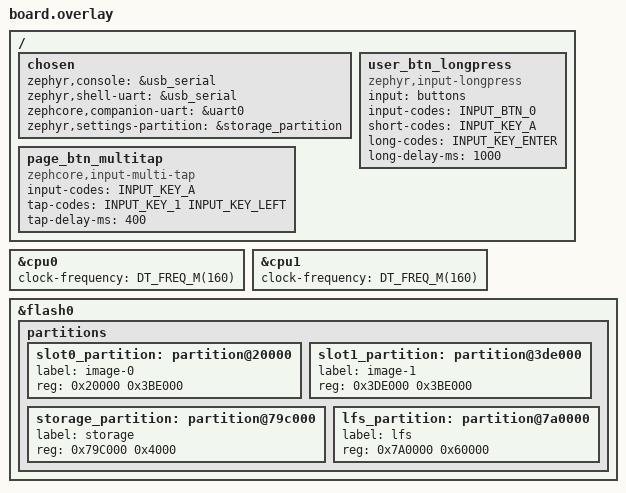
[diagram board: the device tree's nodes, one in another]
/*
 * SPDX-License-Identifier: MIT
 * LilyGo T3S3 v1.x — ZephCore-specific integration
 *
 * This overlay adds ZephCore-specific integration on top of the hardware DTS.
 * All fixed hardware (LoRa, OLED, button, ADC) is in lilygo_t3s3_procpu.dts.
 *
 * Only ZephCore-specific concerns go here:
 * - Input longpress/multitap chains
 * - Flash partition repartitioning for DataStore
 * - USB OTG companion transport
 */

#include <zephyr/dt-bindings/input/input-event-codes.h>

/ {
	chosen {
		/* Keep console/shell on USB Serial/JTAG by default.
		 * When USB OTG is active, esp32s3_console_uart0.dtsi reroutes
		 * to uart0 (GPIO43/44). */
		zephyr,console = &usb_serial;
		zephyr,shell-uart = &usb_serial;
		/* Plain-UART companion backend */
		zephcore,companion-uart = &uart0;
	};

	/* Button chain — longpress + multi-tap */
	user_btn_longpress {
		compatible = "zephyr,input-longpress";
		input = <&buttons>;
		input-codes = <INPUT_BTN_0>;
		short-codes = <INPUT_KEY_A>;
		long-codes = <INPUT_KEY_ENTER>;
		long-delay-ms = <1000>;
	};

	page_btn_multitap {
		compatible = "zephcore,input-multi-tap";
		input-codes = <INPUT_KEY_A>;
		tap-codes = <INPUT_KEY_1 INPUT_KEY_LEFT>;
		tap-delay-ms = <400>;
	};
};

/* Reduce CPU clock from 240 MHz to 160 MHz — saves power, HAL minimum */
&cpu0 {
	clock-frequency = <DT_FREQ_M(160)>;
};

&cpu1 {
	clock-frequency = <DT_FREQ_M(160)>;
};

/*
 * Flash partitions — repartition default ESP32-S3 8MB layout.
 * Delete lpcore, storage, scratch, and coredump partitions to reclaim
 * the 384 KB for LittleFS.
 *
 * 0x7A0000 - 0x7FFFFF (384KB) LittleFS (identity, contacts, channels, BLE bonds)
 */
/delete-node/ &slot0_lpcore_partition;
/delete-node/ &slot1_lpcore_partition;
/delete-node/ &storage_partition;
/delete-node/ &scratch_partition;
/delete-node/ &coredump_partition;
/delete-node/ &slot0_partition;
/delete-node/ &slot1_partition;

/ {
	chosen {
		zephyr,settings-partition = &storage_partition;
	};
};

&flash0 {
	partitions {
		/* App slots — both trimmed 8KB so slot0 == slot1 (16KB total freed
		 * for the NVS partition below), keeping MCUboot swap-mode compatible,
		 * not just overwrite-only.  slot0 start (0x20000) unchanged. */
		slot0_partition: partition@20000 {
			label = "image-0";
			reg = <0x20000 0x3BE000>;
		};
		slot1_partition: partition@3de000 {
			label = "image-1";
			reg = <0x3DE000 0x3BE000>;
		};
		/* BLE bond store — 16KB NVS, isolated from /lfs (see esp32_common.conf).
		 * Carved from the end of slot1 so lfs stays byte-identical. */
		storage_partition: partition@79c000 {
			label = "storage";
			reg = <0x79C000 0x4000>;
		};
		/* LittleFS 384KB for DataStore (identity, prefs, contacts) */
		lfs_partition: partition@7a0000 {
			label = "lfs";
			reg = <0x7A0000 0x60000>;
		};
	};
};

/* LittleFS auto-mount — standard /lfs mount point */
#include "../../common/filesystem.dtsi"

/* USB OTG companion transport. Consoles over USB Serial/JTAG (shares D+/D-
 * with USB OTG), so the console is rerouted to uart0. */
#include "../../common/esp32s3_console_uart0.dtsi"
#include "../../common/esp32s3_usb_otg.dtsi"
